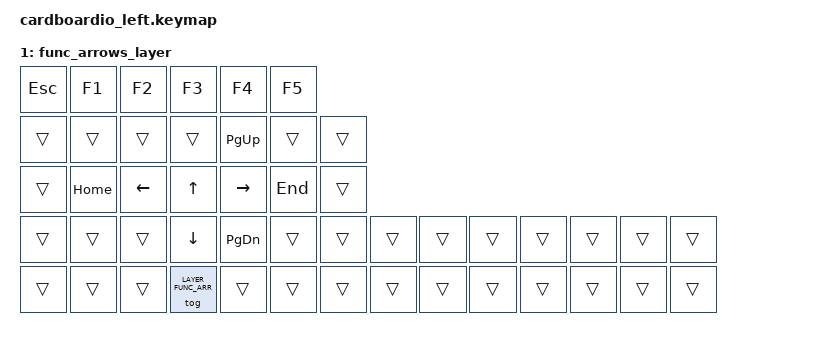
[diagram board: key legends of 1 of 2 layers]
/*
 * Copyright (c) 2020 The ZMK Contributors
 *
 * SPDX-License-Identifier: MIT
 */

#include <behaviors.dtsi>
#include <dt-bindings/zmk/keys.h>
#include <dt-bindings/zmk/bt.h>

#define LAYER_DEFAULT 0
#define LAYER_FUNC_ARR 1

/ {
        behaviors {
                palm: palm_hold_tap {
                        compatible = "zmk,behavior-hold-tap";
                        label = "PALM_HOLD_TAP";
                        binding-cells = <0>;
                        flavor = "balanced";
                        tapping-term-ms = <200>;
                        quick-tap-ms = <200>;
                        bindings = <&tog LAYER_FUNC_ARR>, <&mo LAYER_FUNC_ARR>;
                };

        };

        keymap {
                compatible = "zmk,keymap";

                default_layer {
/* QWERTY
 * .------------------------------------------
 * |   `  |   1  |   2  |   3  |   4  |   5  |       ------
 * |------+------+------+------+------+------+      (      )
 * | Tab  |   Q  |   W  |   E  |   R  |   T  |       ------
 * |------+------+------+------+------+------+   ------
 * | Caps |   A  |   S  |   D  |   F  |   G  |  ( Mute )
 * |------+------+------+------+------+------+   ------
 * | Shift|   Z  |   X  |   C  |   V  |   B  |    +------+
 * |-------------+------+------+------+------+    | ⌦/Alt|
 * | Ctrl | Win  | Alt  |           +------+------+------+
 * .--------------------+           |      | Spc/⇧| ⇥/Ctl|
 *                                  +------+------+------+
 *                      +------+
 *                      |  L1  |
 *                      +------+
 */
                        bindings = <
&kp  GRAVE    &kp  N1       &kp  N2       &kp  N3       &kp  N4                 &kp  N5
&kp  TAB      &kp  Q        &kp  W        &kp  E        &kp  R                  &kp  T             &none
&kp  CAPS     &kp  A        &kp  S        &kp  D        &kp  F                  &kp  G             &kp C_MUTE
&kp  LSHFT    &kp  Z        &kp  X        &kp  C        &kp  V                  &kp  B             &mt LALT DEL
&kp  LCTRL    &kp  LMETA    &kp  LALT     &palm         &none                   &mt LSHFT SPACE    &mt LCTRL TAB
                        >;

                        sensor-bindings = <
                                &inc_dep_kp UP DOWN
                                &inc_dep_kp C_VOL_UP C_VOL_DOWN
                                &inc_dep_kp C_AC_UNDO C_AC_REDO
                        >;
                };
                func_arrows_layer {
/* Esc, function row, and alternate arrow keys
 * .------------------------------------------
 * | Esc  |  F1  |  F2  |  F3  |  F4  |  F5  |       ------
 * |------+------+------+------+------+------+      (      )
 * |      |      |      |      | PgUp |      |       ------
 * |------+------+------+------+------+------+   ------
 * |      | Home |  <-  |   ^  |  ->  | End  |  (      )
 * |------+------+------+------+------+------+   ------
 * |      |      |      |   v  | PgDn |      |    +------+
 * |-------------+------+------+------+------+    |      |
 * |      |      |      |           +------+------+------+
 * .--------------------+           |      |      |      |
 *                                  +------+------+------+
 *                      +------+
 *                      | -L1  |
 *                      +------+
 */
                        bindings = <
&kp  ESC      &kp  F1       &kp  F2       &kp  F3              &kp  F4       &kp  F5
&trans        &trans        &trans        &trans               &kp PG_UP     &trans         &trans
&trans        &kp HOME      &kp LEFT      &kp UP               &kp RIGHT     &kp END        &trans
&trans        &trans        &trans        &kp DOWN             &kp PG_DN     &trans         &trans                  &trans         &trans         &trans         &trans         &trans         &trans         &trans
&trans        &trans        &trans        &tog LAYER_FUNC_ARR  &trans        &trans         &trans                 &trans        &trans         &trans        &trans         &trans         &trans         &trans
                        >;
                        sensor_bindings = <
                                &inc_dep_kp C_AC_SCROLL_UP C_AC_SCROLL_DOWN
                                &trans
                                &trans
                        >;
                };
        };
};

